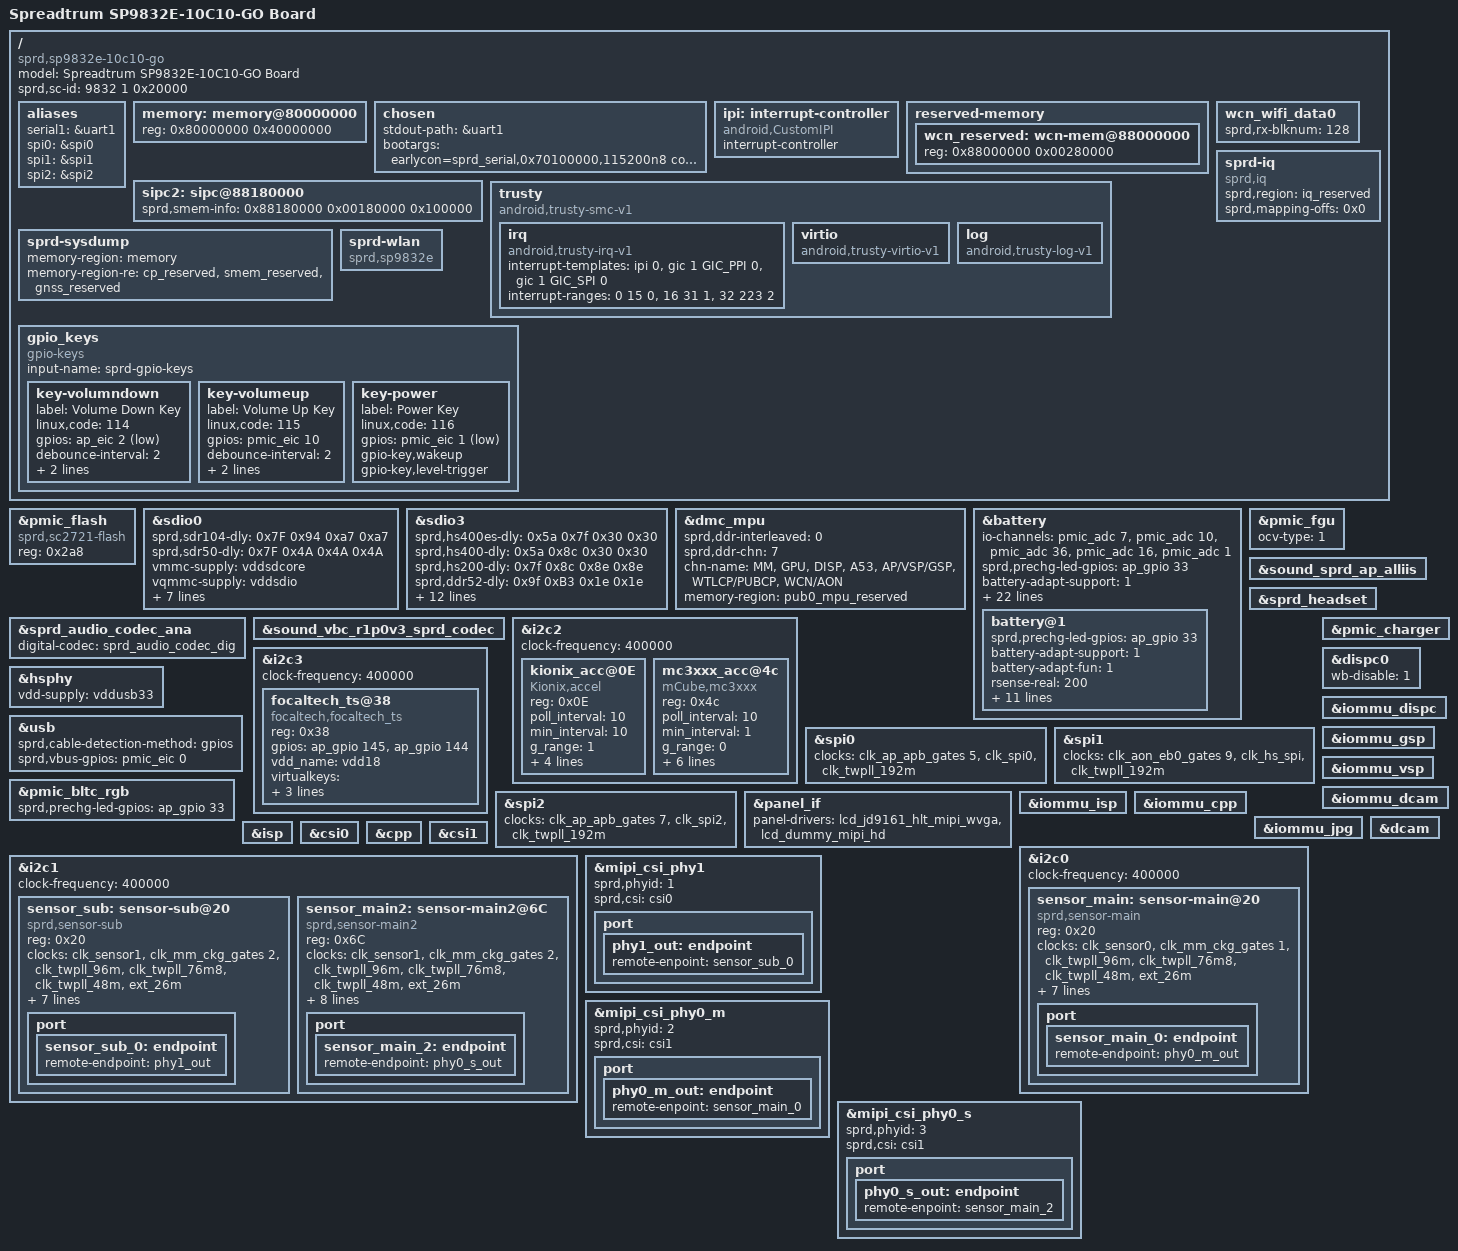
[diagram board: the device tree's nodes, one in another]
/*
 * Spreadtrum sharkle sp9832e board DTS file
 *
 * Copyright (C) 2017, Spreadtrum Communications Inc.
 *
 * This file is licensed under a dual GPLv2 or X11 license.
 */
/dts-v1/;

#include "sc9832e.dtsi"
#include "sp9832e-common.dtsi"
#include "lcd/lcd_jd9161_hlt_mipi_wvga.dtsi"
#include "lcd/lcd_dummy_mipi.dtsi"

/ {
	model = "Spreadtrum SP9832E-10C10-GO Board";

	compatible = "sprd,sp9832e-10c10-go", "sprd,sc9832e";

	sprd,sc-id = <9832 1 0x20000>;

	aliases {
		serial1 = &uart1;
		spi0 = &spi0;
		spi1 = &spi1;
		spi2 = &spi2;
	};

	memory: memory@80000000 {
		device_type = "memory";
		reg = <0x80000000 0x40000000>;
	};

	chosen {
		stdout-path = &uart1;
		bootargs = "earlycon=sprd_serial,0x70100000,115200n8 console=ttyS1,115200n8 loglevel=1 init=/init root=/dev/ram0 rw androidboot.hardware=VFD420";
	};

	ipi: interrupt-controller {
		compatible = "android,CustomIPI";
		#interrupt-cells = <1>;
		interrupt-controller;
	};

	reserved-memory {
		/* must be 32M aligned */
		wcn_reserved: wcn-mem@88000000 {
		      reg = <0x88000000 0x00280000>;
		};
	};

	sipc2: sipc@88180000 {
		/* <ap-addr dst-maped-addr size> */
		sprd,smem-info = <0x88180000 0x00180000 0x100000>;
	};

	wcn_wifi_data0 {
		sprd,rx-blknum = <128>;
	};

	trusty {
		compatible = "android,trusty-smc-v1";

		irq {
			compatible = "android,trusty-irq-v1";
			interrupt-templates = <&ipi 0>,
						<&gic 1 GIC_PPI 0>,
						<&gic 1 GIC_SPI 0>;
			interrupt-ranges = < 0  15 0>,
						<16  31 1>,
						<32 223 2>;
		};

		virtio {
			compatible = "android,trusty-virtio-v1";
		};

		log {
			compatible = "android,trusty-log-v1";
		};
	};

	sprd-iq {
		compatible = "sprd,iq";
		sprd,region = <&iq_reserved>;
		sprd,mapping-offs = <0x0>;
	};

	sprd-sysdump {
		memory-region = <&memory>;
		memory-region-re = <&cp_reserved>, <&smem_reserved>,
				<&gnss_reserved>;
	};

	sprd-wlan {
		 compatible = "sprd,sp9832e";
	};

	gpio_keys {
		compatible = "gpio-keys";
		input-name = "sprd-gpio-keys";
		status = "ok";

		key-volumndown {
			label = "Volume Down Key";
			linux,code = <114>;
			gpios = <&ap_eic 2 1>;
			debounce-interval = <2>;
			gpio-key,wakeup;
			gpio-key,level-trigger;
		};

		key-volumeup {
			label = "Volume Up Key";
			linux,code = <115>;
			gpios = <&pmic_eic 10 0>;
			debounce-interval = <2>;
			gpio-key,wakeup;
			gpio-key,level-trigger;
		};

		key-power {
			label = "Power Key";
			linux,code = <116>;
			gpios = <&pmic_eic 1 1>;
			gpio-key,wakeup;
			gpio-key,level-trigger;
		};
	};
};

&pmic_flash {
	compatible = "sprd,sc2721-flash";
	reg = <0x2a8>;
};

&sdio0 {
	sprd,sdr104-dly = <0x7F 0x94 0xa7 0xa7>;
	sprd,sdr50-dly = <0x7F 0x4A 0x4A 0x4A>;
	vmmc-supply = <&vddsdcore>;
	vqmmc-supply = <&vddsdio>;
	voltage-ranges = <3000 3000>;
	bus-width = <4>;
	cd-gpios = <&ap_gpio 78 1>;
	sd-uhs-sdr50;
	sprd,name = "sdio_sd";
	no-sdio;
	no-mmc;
	status = "okay";
};

&sdio3 {
	sprd,hs400es-dly = <0x5A 0x7F 0x30 0x30>;
	sprd,hs400-dly = <0x5A 0x8C 0x30 0x30>;
	sprd,hs200-dly = <0x7F 0x8C 0x8E 0x8E>;
	sprd,ddr52-dly = <0x9F 0xB3 0x1E 0x1E>;
	vmmc-supply = <&vddemmccore>;
	voltage-ranges = <3000 3000>;
	bus-width = <8>;
	non-removable;
	cap-mmc-hw-reset;
	mmc-hs400-enhanced-strobe;
	mmc-hs400-1_8v;
	mmc-hs200-1_8v;
	mmc-ddr-1_8v;
	sprd,name = "sdio_emmc";
	no-sdio;
	no-sd;
	status = "okay";
};

&dmc_mpu {
	sprd,ddr-interleaved = <0>;
	sprd,ddr-chn = <7>;
	chn-name = "MM", "GPU", "DISP",
		"A53", "AP/VSP/GSP", "WTLCP/PUBCP",
		"WCN/AON";
	memory-region = <&pub0_mpu_reserved>;
};

&sdio3 {
	sprd,hs400es-dly = <0x5a 0x7f 0x30 0x30>;
	sprd,hs400-dly = <0x5a 0x8c 0x30 0x30>;
	sprd,hs200-dly = <0x7f 0x8c 0x8e 0x8e>;
	sprd,ddr52-dly = <0x9f 0xB3 0x1e 0x1e>;
	vmmc-supply = <&vddemmccore>;
	voltage-ranges = <3000 3000>;
	bus-width = <8>;
	non-removable;
	cap-mmc-hw-reset;
	sprd,name = "sdio_emmc";
	no-sdio;
	no-sd;
	status = "okay";
};

&battery {
	io-channels = <&pmic_adc 7>,<&pmic_adc 10>,
			<&pmic_adc 36>,<&pmic_adc 16>,<&pmic_adc 1>;
	io-channel-names = "adc_temp","adc_vbat",
			"adc_vchg","adc_isense","adc_id";
	sprd,prechg-led-gpios = <&ap_gpio 33 0>;
	battery-adapt-support = <1>;
	battery-adapt-fun = <1>;
	adp-cdp-cur = <800>;
	adp-dcp-cur = <800>;
	adp-sdp-cur = <450>;
	adp-unknown-cur = <450>;
	chg-end-vol = <4350>;
	chg-end-vol-check = <4330>;
	chg-bat-safety-vol = <4430>;
	rechg-vol = <4270>;
	rsense-real = <200>;
	rint = <369>;
	cnom = <1610>;
	chg-polling-time = <10>;
	jeita-temp-tab = <1000 1100 1150 1450 1580>;
	jeita-temp-recovery-tab = <1030 1130 1180 1420 1550>;
	jeita-cur-tab = <0 480 800 800 400 0>;
	jeita-cccv-tab = <4350 4350 4350 4350 4100 4100>;
	ocv-tab-vol = <4312 4250 4197 4146 4097 4061 3997
			3963 3931 3878 3846 3824 3806 3792
			3778 3763 3745 3720 3691 3681 3400>;
	ocv-tab-cap = <100  95   90   85   80   75   70
			65   60   55   50   45   40   35
			30   25   20   15   10   5   0>;

	battery@1 {
		sprd,prechg-led-gpios = <&ap_gpio 33 0>;
		battery-adapt-support = <1>;
		battery-adapt-fun = <1>;
		rsense-real = <200>;
		rint = <300>;
		cnom = <1562>;
		jeita-temp-tab = <1000 1100 1150 1450 1580>;
		jeita-temp-recovery-tab = <1030 1130 1180 1420 1550>;
		jeita-cur-tab = <0 480 800 800 400 0>;
		jeita-cccv-tab = <4350 4350 4350 4350 4100 4100>;
		ocv-tab-vol = <4316 4257 4204 4153 4103 4067 3999
                        3968 3924 3875 3847 3825 3807 3792
                        3779 3764 3744 3711 3691 3680 3400>;
		ocv-tab-cap = <100  95   90   85   80   75   70
                        65   60   55   50   45   40   35
                        30   25   20   15   10   5   0>;
	};
};

&pmic_fgu {
	ocv-type = <1>;
};

&sprd_audio_codec_ana {
	status = "okay";
	digital-codec = <&sprd_audio_codec_dig>;
};

&sound_vbc_r1p0v3_sprd_codec {
	status = "okay";
};

&sound_sprd_ap_alliis {
	status = "okay";
};

&sprd_headset {
	status = "okay";
};

&i2c2 {
	status = "okay";
	clock-frequency = <400000>;
	kionix_acc@0E{
		compatible = "Kionix,accel";
		reg = <0x0E>;
		poll_interval = <10>;
		min_interval = <10>;
		g_range = <1>;
		accel_res = <0>;
		accel_irq_use_drdy = <1>;
		accel_direction = <6>;
		gpios = <&ap_gpio 55 0>;
	};
	mc3xxx_acc@4c{
		compatible = "mCube,mc3xxx";
		reg = <0x4c>;
		poll_interval = <10>;
		min_interval = <1>;
		g_range = <0>;
		axis_maps_x = <0>;
		axis_maps_y = <1>;
		axis_maps_z = <2>;
		negate_x = <1>;
		negate_y = <1>;
		negate_z = <0>;
	};
};

&i2c3 {
	status = "okay";
	clock-frequency = <400000>;
	focaltech_ts@38{
		status = "okay";
		compatible = "focaltech,focaltech_ts";
		reg = <0x38>;
		gpios = <&ap_gpio 145 0
			&ap_gpio 144 0>;
		vdd_name = "vdd18";
		virtualkeys = <80 900 30 30
			240 900 30 30
			400 900 30 30>;
		TP_MAX_X = <480>;
		TP_MAX_Y = <800>;
	};
};


&spi0 {
	/*used for fingerprint sensor*/
	status = "okay";
	clocks = <&clk_ap_apb_gates 5>, <&clk_spi0>, <&clk_twpll_192m>;
};

&spi1 {
	clocks = <&clk_aon_eb0_gates 9>, <&clk_hs_spi>, <&clk_twpll_192m>;
};

&spi2 {
	clocks = <&clk_ap_apb_gates 7>, <&clk_spi2>, <&clk_twpll_192m>;
};

&hsphy {
	vdd-supply = <&vddusb33>;
};

&usb {
	sprd,cable-detection-method = "gpios";
	sprd,vbus-gpios = <&pmic_eic 0 0>;
};

&pmic_charger {
	status = "okay";
};

&pmic_bltc_rgb {
	status = "okay";
	sprd,prechg-led-gpios = <&ap_gpio 33 0>;
};

&dispc0 {
	wb-disable = <1>;
};

&iommu_dispc {
	status = "okay";
};

&panel_if {
	panel-drivers = <
			&lcd_jd9161_hlt_mipi_wvga
			&lcd_dummy_mipi_hd
		>;
};

&iommu_gsp {
	status = "okay";
};

&iommu_vsp {
	status = "okay";
};

&iommu_dcam {
	status = "okay";
};

&iommu_isp {
	status = "okay";
};

&iommu_cpp {
	status = "okay";
};

&iommu_jpg {
	status = "okay";
};

&dcam {
	status = "okay";
};

&isp {
	status = "okay";
};

&csi0 {
	status = "okay";
};

&cpp {
	status = "okay";
};

&csi1 {
	status = "okay";
};

&i2c0 {
	status = "okay";
	clock-frequency = <400000>;

	sensor_main: sensor-main@20 {
		compatible = "sprd,sensor-main";
		reg = <0x20>;
		clock-names = "clk_src","sensor_eb",
			"clk_96m","clk_76m8",
			"clk_48m","clk_26m";
		clocks = <&clk_sensor0>, <&clk_mm_ckg_gates 1>,
			<&clk_twpll_96m>,<&clk_twpll_76m8>,
			<&clk_twpll_48m>,<&ext_26m>;
		vddio-supply = <&vddcamio>;
		vddcama-supply = <&vddcama>;
		vddcamd-supply = <&vddcamd>;
		vddcammot-supply = <&vddcammot>;
		reset-gpios = <&ap_gpio 44 0>;
		power-down-gpios = <&ap_gpio 46 0>;
		host = "dcam1";
		port {
			sensor_main_0: endpoint {
				remote-endpoint = <&phy0_m_out>;
			};
		};
	};
};

&i2c1 {
	status = "okay";
	clock-frequency = <400000>;

	sensor_sub: sensor-sub@20 {
		compatible = "sprd,sensor-sub";
		reg = <0x20>;
		clock-names = "clk_src","sensor_eb",
				"clk_96m","clk_76m8",
				"clk_48m","clk_26m";
		clocks = <&clk_sensor1>, <&clk_mm_ckg_gates 2>,
			<&clk_twpll_96m>,<&clk_twpll_76m8>,
			<&clk_twpll_48m>,<&ext_26m>;
		vddio-supply = <&vddcamio>;
		vddcama-supply = <&vddcama>;
		vddcamd-supply = <&vddcamd>;
		vddcammot-supply = <&vddcammot>;
		reset-gpios = <&ap_gpio 45 0>;
		power-down-gpios = <&ap_gpio 47 0>;
		host = "dcam0";
		port {
			sensor_sub_0: endpoint {
				remote-endpoint = <&phy1_out>;
			};
		};
	};

	sensor_main2: sensor-main2@6C {
		compatible = "sprd,sensor-main2";
		reg = <0x6C>;
		clock-names = "clk_src","sensor_eb",
				"clk_96m","clk_76m8",
				"clk_48m","clk_26m";
		clocks = <&clk_sensor1>, <&clk_mm_ckg_gates 2>,
			<&clk_twpll_96m>,<&clk_twpll_76m8>,
			<&clk_twpll_48m>,<&ext_26m>;
		vddio-supply = <&vddcamio>;
		vddcama-supply = <&vddcama>;
		vddcamd-supply = <&vddcamd>;
		vddcammot-supply = <&vddcammot>;
		reset-gpios = <&ap_gpio 41 0>;
		power-down-gpios = <&ap_gpio 40 0>;
		dvdd-gpios = <&ap_gpio 62 0>;
		host = "dcam1";
		port {
			sensor_main_2: endpoint {
				remote-endpoint = <&phy0_s_out>;
			};
		};
	};
};

&mipi_csi_phy1 {
	status = "okay";
	sprd,phyid = <1>;
	sprd,csi = <&csi0>;
	port {
	phy1_out: endpoint {
		remote-enpoint = <&sensor_sub_0>;
		};
	};
};

&mipi_csi_phy0_m {
	status = "okay";
	sprd,phyid = <2>;
	sprd,csi = <&csi1>;
	port {
		phy0_m_out: endpoint {
			remote-enpoint = <&sensor_main_0>;
		};
	};
};

&mipi_csi_phy0_s {
	status = "okay";
	sprd,phyid = <3>;
	sprd,csi = <&csi1>;
	port {
		phy0_s_out: endpoint {
			remote-enpoint = <&sensor_main_2>;
		};
	};
};
